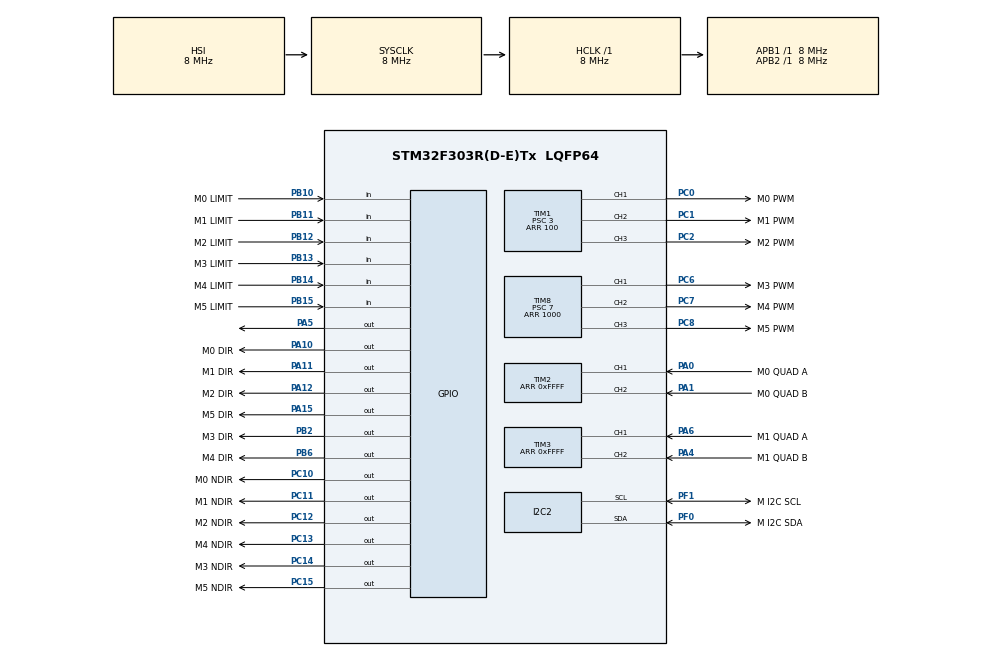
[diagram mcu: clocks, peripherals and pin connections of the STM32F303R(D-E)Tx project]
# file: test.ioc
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Mcu.Family=STM32F3
Mcu.Name=STM32F303R(D-E)Tx
Mcu.Package=LQFP64
Mcu.UserConstants=CONTROL_LOOP_PERIOD,1000;I2C_ADDRESS,0x10;CHANNELS,6;QUADRATURE_FILTER,8;PWM_PERIOD,10000
NVIC.PriorityGroup=NVIC_PRIORITYGROUP_4
NVIC.TIM6_DAC_IRQn=true\:1\:0\:true\:false\:true\:true\:true\:true
PA0.GPIO_Label=M0 QUAD A
PA0.Signal=S_TIM2_CH1_ETR
PA1.GPIO_Label=M0 QUAD B
PA1.Signal=S_TIM2_CH2
PA10.GPIO_Label=M0 DIR
PA10.Signal=GPIO_Output
PA11.GPIO_Label=M1 DIR
PA11.Signal=GPIO_Output
PA12.GPIO_Label=M2 DIR
PA12.Signal=GPIO_Output
PA15.GPIO_Label=M5 DIR
PA15.Signal=GPIO_Output
PA4.GPIO_Label=M1 QUAD B
PA4.Signal=S_TIM3_CH2
PA5.Signal=GPIO_Output
PA6.GPIO_Label=M1 QUAD A
PA6.Signal=S_TIM3_CH1
PB10.GPIO_Label=M0 LIMIT
PB10.GPIO_PuPd=GPIO_PULLUP
PB10.Signal=GPIO_Input
PB11.GPIO_Label=M1 LIMIT
PB11.GPIO_PuPd=GPIO_PULLUP
PB11.Signal=GPIO_Input
PB12.GPIO_Label=M2 LIMIT
PB12.GPIO_PuPd=GPIO_PULLUP
PB12.Signal=GPIO_Input
PB13.GPIO_Label=M3 LIMIT
PB13.GPIO_PuPd=GPIO_PULLUP
PB13.Signal=GPIO_Input
PB14.GPIO_Label=M4 LIMIT
PB14.GPIO_PuPd=GPIO_PULLUP
PB14.Signal=GPIO_Input
PB15.GPIO_Label=M5 LIMIT
PB15.GPIO_PuPd=GPIO_PULLUP
PB15.Signal=GPIO_Input
PB2.GPIO_Label=M3 DIR
PB2.Signal=GPIO_Output
PB6.GPIO_Label=M4 DIR
PB6.Signal=GPIO_Output
PB8.GPIO_Label=J I2C SCL
PB8.GPIO_Pu=GPIO_PULLUP
PB8.Signal=I2C1_SCL
PB9.GPIO_Label=J I2C SDA
PB9.GPIO_Pu=GPIO_PULLUP
PB9.Signal=I2C1_SDA
PC0.GPIO_Label=M0 PWM
PC0.Signal=S_TIM1_CH1
PC1.GPIO_Label=M1 PWM
PC1.Signal=S_TIM1_CH2
PC10.GPIO_Label=M0 NDIR
PC10.Signal=GPIO_Output
PC11.GPIO_Label=M1 NDIR
PC11.Signal=GPIO_Output
PC12.GPIO_Label=M2 NDIR
PC12.Signal=GPIO_Output
PC13.GPIO_Label=M4 NDIR
PC13.Signal=GPIO_Output
PC14-OSC32_IN.GPIO_Label=M3 NDIR
PC14-OSC32_IN.Signal=GPIO_Output
PC15-OSC32_OUT.GPIO_Label=M5 NDIR
PC15-OSC32_OUT.Signal=GPIO_Output
PC2.GPIO_Label=M2 PWM
PC2.Signal=S_TIM1_CH3
PC6.GPIO_Label=M3 PWM
PC6.Signal=S_TIM8_CH1
PC7.GPIO_Label=M4 PWM
PC7.Signal=S_TIM8_CH2
PC8.GPIO_Label=M5 PWM
PC8.Signal=S_TIM8_CH3
PF0-OSC_IN.GPIO_Label=M I2C SDA
PF0-OSC_IN.GPIO_Pu=GPIO_PULLUP
PF0-OSC_IN.Mode=I2C
PF0-OSC_IN.Signal=I2C2_SDA
PF1-OSC_OUT.GPIO_Label=M I2C SCL
PF1-OSC_OUT.GPIO_Pu=GPIO_PULLUP
PF1-OSC_OUT.Mode=I2C
PF1-OSC_OUT.Signal=I2C2_SCL
ProjectManager.HeapSize=0x200
ProjectManager.StackSize=0x400
ProjectManager.TargetToolchain=STM32CubeIDE
RCC.AHBFreq_Value=8000000
RCC.APB1Freq_Value=8000000
RCC.APB2Freq_Value=8000000
RCC.CortexFreq_Value=8000000
RCC.HSE_VALUE=8000000
RCC.HSI_VALUE=8000000
RCC.LSE_VALUE=32768
RCC.SYSCLKFreq_VALUE=8000000
RCC.USBFreq_Value=16000000
SH.S_TIM1_CH1.0=TIM1_CH1,PWM Generation1 CH1
SH.S_TIM1_CH2.0=TIM1_CH2,PWM Generation2 CH2
SH.S_TIM1_CH3.0=TIM1_CH3,PWM Generation3 CH3
SH.S_TIM2_CH1_ETR.0=TIM2_CH1,Encoder_Interface
SH.S_TIM2_CH2.0=TIM2_CH2,Encoder_Interface
SH.S_TIM3_CH1.0=TIM3_CH1,Encoder_Interface
SH.S_TIM3_CH2.0=TIM3_CH2,Encoder_Interface
SH.S_TIM8_CH1.0=TIM8_CH1,PWM Generation1 CH1
SH.S_TIM8_CH2.0=TIM8_CH2,PWM Generation2 CH2
SH.S_TIM8_CH3.0=TIM8_CH3,PWM Generation3 CH3
TIM1.Channel-PWM\ Generation1\ CH1=TIM_CHANNEL_1
TIM1.Channel-PWM\ Generation2\ CH2=TIM_CHANNEL_2
TIM1.Channel-PWM\ Generation3\ CH3=TIM_CHANNEL_3
TIM1.Period=100
TIM1.Prescaler=3
TIM2.IC1Filter=QUADRATURE_FILTER
TIM2.IC2Filter=QUADRATURE_FILTER
TIM2.Period=0xFFFF
TIM3.IC1Filter=QUADRATURE_FILTER
TIM3.IC2Filter=QUADRATURE_FILTER
TIM3.Period=0xFFFF
TIM6.Period=CONTROL_LOOP_PERIOD
TIM6.Prescaler=7
TIM8.Channel-PWM\ Generation1\ CH1=TIM_CHANNEL_1
TIM8.Channel-PWM\ Generation2\ CH2=TIM_CHANNEL_2
TIM8.Channel-PWM\ Generation3\ CH3=TIM_CHANNEL_3
TIM8.Period=1000
TIM8.Prescaler=7
VP_TIM1_VS_ClockSourceINT.Mode=Internal
VP_TIM6_VS_ClockSourceINT.Mode=Enable_Timer
VP_TIM8_VS_ClockSourceINT.Mode=Internal
board=custom

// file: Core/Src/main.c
/* USER CODE BEGIN Header */
/**
  ******************************************************************************
  * @file           : main.c
  * @brief          : Main program body
  ******************************************************************************
  * @attention
  *
  * <h2><center>&copy; Copyright (c) 2022 STMicroelectronics.
  * All rights reserved.</center></h2>
  *
  * This software component is licensed by ST under BSD 3-Clause license,
  * the "License"; You may not use this file except in compliance with the
  * License. You may obtain a copy of the License at:
  *                        opensource.org/licenses/BSD-3-Clause
  *
  ******************************************************************************
  */
/* USER CODE END Header */
#include "main.h"

I2C_HandleTypeDef hi2c2;

TIM_HandleTypeDef htim1;
TIM_HandleTypeDef htim2;
TIM_HandleTypeDef htim3;
TIM_HandleTypeDef htim6;
TIM_HandleTypeDef htim8;

void SystemClock_Config(void);
static void MX_GPIO_Init(void);
static void MX_I2C2_Init(void);
static void MX_TIM1_Init(void);
static void MX_TIM2_Init(void);
static void MX_TIM3_Init(void);
static void MX_TIM8_Init(void);
static void MX_TIM6_Init(void);

int main(void)
{

  /* MCU Configuration--------------------------------------------------------*/

  /* Reset of all peripherals, Initializes the Flash interface and the Systick. */
  HAL_Init();

  /* Configure the system clock */
  SystemClock_Config();

  /* Initialize all configured peripherals */
  MX_GPIO_Init();
  MX_I2C2_Init();
  MX_TIM1_Init();
  MX_TIM2_Init();
  MX_TIM3_Init();
  MX_TIM8_Init();
  MX_TIM6_Init();

  /* Infinite loop */
  /* USER CODE BEGIN WHILE */
  while (1)
  {
	  uint8_t buffer = 0xCC;
	  HAL_I2C_Master_Transmit(&hi2c2, 0x80, &buffer, sizeof(buffer), 100);
    /* USER CODE END WHILE */

  }
}

void SystemClock_Config(void)
{
  RCC_OscInitTypeDef RCC_OscInitStruct = {0};
  RCC_ClkInitTypeDef RCC_ClkInitStruct = {0};
  RCC_PeriphCLKInitTypeDef PeriphClkInit = {0};

  /** Initializes the RCC Oscillators according to the specified parameters
  * in the RCC_OscInitTypeDef structure.
  */
  RCC_OscInitStruct.OscillatorType = RCC_OSCILLATORTYPE_HSI;
  RCC_OscInitStruct.HSIState = RCC_HSI_ON;
  RCC_OscInitStruct.HSICalibrationValue = RCC_HSICALIBRATION_DEFAULT;
  RCC_OscInitStruct.PLL.PLLState = RCC_PLL_NONE;
  if (HAL_RCC_OscConfig(&RCC_OscInitStruct) != HAL_OK)
  {
    Error_Handler();
  }
  /** Initializes the CPU, AHB and APB buses clocks
  */
  RCC_ClkInitStruct.ClockType = RCC_CLOCKTYPE_HCLK|RCC_CLOCKTYPE_SYSCLK
                              |RCC_CLOCKTYPE_PCLK1|RCC_CLOCKTYPE_PCLK2;
  RCC_ClkInitStruct.SYSCLKSource = RCC_SYSCLKSOURCE_HSI;
  RCC_ClkInitStruct.AHBCLKDivider = RCC_SYSCLK_DIV1;
  RCC_ClkInitStruct.APB1CLKDivider = RCC_HCLK_DIV1;
  RCC_ClkInitStruct.APB2CLKDivider = RCC_HCLK_DIV1;

  if (HAL_RCC_ClockConfig(&RCC_ClkInitStruct, FLASH_LATENCY_0) != HAL_OK)
  {
    Error_Handler();
  }
  PeriphClkInit.PeriphClockSelection = RCC_PERIPHCLK_I2C2|RCC_PERIPHCLK_TIM1
                              |RCC_PERIPHCLK_TIM8|RCC_PERIPHCLK_TIM2
                              |RCC_PERIPHCLK_TIM34;
  PeriphClkInit.I2c2ClockSelection = RCC_I2C2CLKSOURCE_HSI;
  PeriphClkInit.Tim1ClockSelection = RCC_TIM1CLK_HCLK;
  PeriphClkInit.Tim8ClockSelection = RCC_TIM8CLK_HCLK;
  PeriphClkInit.Tim2ClockSelection = RCC_TIM2CLK_HCLK;
  PeriphClkInit.Tim34ClockSelection = RCC_TIM34CLK_HCLK;
  if (HAL_RCCEx_PeriphCLKConfig(&PeriphClkInit) != HAL_OK)
  {
    Error_Handler();
  }
}

static void MX_I2C2_Init(void)
{

  hi2c2.Instance = I2C2;
  hi2c2.Init.Timing = 0x2000090E;
  hi2c2.Init.OwnAddress1 = 0;
  hi2c2.Init.AddressingMode = I2C_ADDRESSINGMODE_7BIT;
  hi2c2.Init.DualAddressMode = I2C_DUALADDRESS_DISABLE;
  hi2c2.Init.OwnAddress2 = 0;
  hi2c2.Init.OwnAddress2Masks = I2C_OA2_NOMASK;
  hi2c2.Init.GeneralCallMode = I2C_GENERALCALL_DISABLE;
  hi2c2.Init.NoStretchMode = I2C_NOSTRETCH_DISABLE;
  if (HAL_I2C_Init(&hi2c2) != HAL_OK)
  {
    Error_Handler();
  }
  /** Configure Analogue filter
  */
  if (HAL_I2CEx_ConfigAnalogFilter(&hi2c2, I2C_ANALOGFILTER_ENABLE) != HAL_OK)
  {
    Error_Handler();
  }
  /** Configure Digital filter
  */
  if (HAL_I2CEx_ConfigDigitalFilter(&hi2c2, 0) != HAL_OK)
  {
    Error_Handler();
  }

}

static void MX_TIM1_Init(void)
{

  TIM_ClockConfigTypeDef sClockSourceConfig = {0};
  TIM_MasterConfigTypeDef sMasterConfig = {0};
  TIM_OC_InitTypeDef sConfigOC = {0};
  TIM_BreakDeadTimeConfigTypeDef sBreakDeadTimeConfig = {0};

  htim1.Instance = TIM1;
  htim1.Init.Prescaler = 3;
  htim1.Init.CounterMode = TIM_COUNTERMODE_UP;
  htim1.Init.Period = 100;
  htim1.Init.ClockDivision = TIM_CLOCKDIVISION_DIV1;
  htim1.Init.RepetitionCounter = 0;
  htim1.Init.AutoReloadPreload = TIM_AUTORELOAD_PRELOAD_DISABLE;
  if (HAL_TIM_Base_Init(&htim1) != HAL_OK)
  {
    Error_Handler();
  }
  sClockSourceConfig.ClockSource = TIM_CLOCKSOURCE_INTERNAL;
  if (HAL_TIM_ConfigClockSource(&htim1, &sClockSourceConfig) != HAL_OK)
  {
    Error_Handler();
  }
  if (HAL_TIM_PWM_Init(&htim1) != HAL_OK)
  {
    Error_Handler();
  }
  sMasterConfig.MasterOutputTrigger = TIM_TRGO_RESET;
  sMasterConfig.MasterOutputTrigger2 = TIM_TRGO2_RESET;
  sMasterConfig.MasterSlaveMode = TIM_MASTERSLAVEMODE_DISABLE;
  if (HAL_TIMEx_MasterConfigSynchronization(&htim1, &sMasterConfig) != HAL_OK)
  {
    Error_Handler();
  }
  sConfigOC.OCMode = TIM_OCMODE_PWM1;
  sConfigOC.Pulse = 0;
  sConfigOC.OCPolarity = TIM_OCPOLARITY_HIGH;
  sConfigOC.OCNPolarity = TIM_OCNPOLARITY_HIGH;
  sConfigOC.OCFastMode = TIM_OCFAST_DISABLE;
  sConfigOC.OCIdleState = TIM_OCIDLESTATE_RESET;
  sConfigOC.OCNIdleState = TIM_OCNIDLESTATE_RESET;
  if (HAL_TIM_PWM_ConfigChannel(&htim1, &sConfigOC, TIM_CHANNEL_1) != HAL_OK)
  {
    Error_Handler();
  }
  if (HAL_TIM_PWM_ConfigChannel(&htim1, &sConfigOC, TIM_CHANNEL_2) != HAL_OK)
  {
    Error_Handler();
  }
  if (HAL_TIM_PWM_ConfigChannel(&htim1, &sConfigOC, TIM_CHANNEL_3) != HAL_OK)
  {
    Error_Handler();
  }
  sBreakDeadTimeConfig.OffStateRunMode = TIM_OSSR_DISABLE;
  sBreakDeadTimeConfig.OffStateIDLEMode = TIM_OSSI_DISABLE;
  sBreakDeadTimeConfig.LockLevel = TIM_LOCKLEVEL_OFF;
  sBreakDeadTimeConfig.DeadTime = 0;
  sBreakDeadTimeConfig.BreakState = TIM_BREAK_DISABLE;
  sBreakDeadTimeConfig.BreakPolarity = TIM_BREAKPOLARITY_HIGH;
  sBreakDeadTimeConfig.BreakFilter = 0;
  sBreakDeadTimeConfig.Break2State = TIM_BREAK2_DISABLE;
  sBreakDeadTimeConfig.Break2Polarity = TIM_BREAK2POLARITY_HIGH;
  sBreakDeadTimeConfig.Break2Filter = 0;
  sBreakDeadTimeConfig.AutomaticOutput = TIM_AUTOMATICOUTPUT_DISABLE;
  if (HAL_TIMEx_ConfigBreakDeadTime(&htim1, &sBreakDeadTimeConfig) != HAL_OK)
  {
    Error_Handler();
  }
  HAL_TIM_MspPostInit(&htim1);

}

static void MX_TIM2_Init(void)
{

  TIM_Encoder_InitTypeDef sConfig = {0};
  TIM_MasterConfigTypeDef sMasterConfig = {0};

  htim2.Instance = TIM2;
  htim2.Init.Prescaler = 0;
  htim2.Init.CounterMode = TIM_COUNTERMODE_UP;
  htim2.Init.Period = 0xFFFF;
  htim2.Init.ClockDivision = TIM_CLOCKDIVISION_DIV1;
  htim2.Init.AutoReloadPreload = TIM_AUTORELOAD_PRELOAD_DISABLE;
  sConfig.EncoderMode = TIM_ENCODERMODE_TI1;
  sConfig.IC1Polarity = TIM_ICPOLARITY_RISING;
  sConfig.IC1Selection = TIM_ICSELECTION_DIRECTTI;
  sConfig.IC1Prescaler = TIM_ICPSC_DIV1;
  sConfig.IC1Filter = QUADRATURE_FILTER;
  sConfig.IC2Polarity = TIM_ICPOLARITY_RISING;
  sConfig.IC2Selection = TIM_ICSELECTION_DIRECTTI;
  sConfig.IC2Prescaler = TIM_ICPSC_DIV1;
  sConfig.IC2Filter = QUADRATURE_FILTER;
  if (HAL_TIM_Encoder_Init(&htim2, &sConfig) != HAL_OK)
  {
    Error_Handler();
  }
  sMasterConfig.MasterOutputTrigger = TIM_TRGO_RESET;
  sMasterConfig.MasterSlaveMode = TIM_MASTERSLAVEMODE_DISABLE;
  if (HAL_TIMEx_MasterConfigSynchronization(&htim2, &sMasterConfig) != HAL_OK)
  {
    Error_Handler();
  }

}

static void MX_TIM3_Init(void)
{

  TIM_Encoder_InitTypeDef sConfig = {0};
  TIM_MasterConfigTypeDef sMasterConfig = {0};

  htim3.Instance = TIM3;
  htim3.Init.Prescaler = 0;
  htim3.Init.CounterMode = TIM_COUNTERMODE_UP;
  htim3.Init.Period = 0xFFFF;
  htim3.Init.ClockDivision = TIM_CLOCKDIVISION_DIV1;
  htim3.Init.AutoReloadPreload = TIM_AUTORELOAD_PRELOAD_DISABLE;
  sConfig.EncoderMode = TIM_ENCODERMODE_TI1;
  sConfig.IC1Polarity = TIM_ICPOLARITY_RISING;
  sConfig.IC1Selection = TIM_ICSELECTION_DIRECTTI;
  sConfig.IC1Prescaler = TIM_ICPSC_DIV1;
  sConfig.IC1Filter = QUADRATURE_FILTER;
  sConfig.IC2Polarity = TIM_ICPOLARITY_RISING;
  sConfig.IC2Selection = TIM_ICSELECTION_DIRECTTI;
  sConfig.IC2Prescaler = TIM_ICPSC_DIV1;
  sConfig.IC2Filter = QUADRATURE_FILTER;
  if (HAL_TIM_Encoder_Init(&htim3, &sConfig) != HAL_OK)
  {
    Error_Handler();
  }
  sMasterConfig.MasterOutputTrigger = TIM_TRGO_RESET;
  sMasterConfig.MasterSlaveMode = TIM_MASTERSLAVEMODE_DISABLE;
  if (HAL_TIMEx_MasterConfigSynchronization(&htim3, &sMasterConfig) != HAL_OK)
  {
    Error_Handler();
  }

}

static void MX_TIM6_Init(void)
{

  TIM_MasterConfigTypeDef sMasterConfig = {0};

  htim6.Instance = TIM6;
  htim6.Init.Prescaler = 7;
  htim6.Init.CounterMode = TIM_COUNTERMODE_UP;
  htim6.Init.Period = CONTROL_LOOP_PERIOD;
  htim6.Init.AutoReloadPreload = TIM_AUTORELOAD_PRELOAD_DISABLE;
  if (HAL_TIM_Base_Init(&htim6) != HAL_OK)
  {
    Error_Handler();
  }
  sMasterConfig.MasterOutputTrigger = TIM_TRGO_RESET;
  sMasterConfig.MasterSlaveMode = TIM_MASTERSLAVEMODE_DISABLE;
  if (HAL_TIMEx_MasterConfigSynchronization(&htim6, &sMasterConfig) != HAL_OK)
  {
    Error_Handler();
  }

}

static void MX_TIM8_Init(void)
{

  TIM_ClockConfigTypeDef sClockSourceConfig = {0};
  TIM_MasterConfigTypeDef sMasterConfig = {0};
  TIM_OC_InitTypeDef sConfigOC = {0};
  TIM_BreakDeadTimeConfigTypeDef sBreakDeadTimeConfig = {0};

  htim8.Instance = TIM8;
  htim8.Init.Prescaler = 7;
  htim8.Init.CounterMode = TIM_COUNTERMODE_UP;
  htim8.Init.Period = 1000;
  htim8.Init.ClockDivision = TIM_CLOCKDIVISION_DIV1;
  htim8.Init.RepetitionCounter = 0;
  htim8.Init.AutoReloadPreload = TIM_AUTORELOAD_PRELOAD_DISABLE;
  if (HAL_TIM_Base_Init(&htim8) != HAL_OK)
  {
    Error_Handler();
  }
  sClockSourceConfig.ClockSource = TIM_CLOCKSOURCE_INTERNAL;
  if (HAL_TIM_ConfigClockSource(&htim8, &sClockSourceConfig) != HAL_OK)
  {
    Error_Handler();
  }
  if (HAL_TIM_PWM_Init(&htim8) != HAL_OK)
  {
    Error_Handler();
  }
  sMasterConfig.MasterOutputTrigger = TIM_TRGO_RESET;
  sMasterConfig.MasterOutputTrigger2 = TIM_TRGO2_RESET;
  sMasterConfig.MasterSlaveMode = TIM_MASTERSLAVEMODE_DISABLE;
  if (HAL_TIMEx_MasterConfigSynchronization(&htim8, &sMasterConfig) != HAL_OK)
  {
    Error_Handler();
  }
  sConfigOC.OCMode = TIM_OCMODE_PWM1;
  sConfigOC.Pulse = 0;
  sConfigOC.OCPolarity = TIM_OCPOLARITY_HIGH;
  sConfigOC.OCNPolarity = TIM_OCNPOLARITY_HIGH;
  sConfigOC.OCFastMode = TIM_OCFAST_DISABLE;
  sConfigOC.OCIdleState = TIM_OCIDLESTATE_RESET;
  sConfigOC.OCNIdleState = TIM_OCNIDLESTATE_RESET;
  if (HAL_TIM_PWM_ConfigChannel(&htim8, &sConfigOC, TIM_CHANNEL_1) != HAL_OK)
  {
    Error_Handler();
  }
  if (HAL_TIM_PWM_ConfigChannel(&htim8, &sConfigOC, TIM_CHANNEL_2) != HAL_OK)
  {
    Error_Handler();
  }
  if (HAL_TIM_PWM_ConfigChannel(&htim8, &sConfigOC, TIM_CHANNEL_3) != HAL_OK)
  {
    Error_Handler();
  }
  sBreakDeadTimeConfig.OffStateRunMode = TIM_OSSR_DISABLE;
  sBreakDeadTimeConfig.OffStateIDLEMode = TIM_OSSI_DISABLE;
  sBreakDeadTimeConfig.LockLevel = TIM_LOCKLEVEL_OFF;
  sBreakDeadTimeConfig.DeadTime = 0;
  sBreakDeadTimeConfig.BreakState = TIM_BREAK_DISABLE;
  sBreakDeadTimeConfig.BreakPolarity = TIM_BREAKPOLARITY_HIGH;
  sBreakDeadTimeConfig.BreakFilter = 0;
  sBreakDeadTimeConfig.Break2State = TIM_BREAK2_DISABLE;
  sBreakDeadTimeConfig.Break2Polarity = TIM_BREAK2POLARITY_HIGH;
  sBreakDeadTimeConfig.Break2Filter = 0;
  sBreakDeadTimeConfig.AutomaticOutput = TIM_AUTOMATICOUTPUT_DISABLE;
  if (HAL_TIMEx_ConfigBreakDeadTime(&htim8, &sBreakDeadTimeConfig) != HAL_OK)
  {
    Error_Handler();
  }
  HAL_TIM_MspPostInit(&htim8);

}

static void MX_GPIO_Init(void)
{
  GPIO_InitTypeDef GPIO_InitStruct = {0};

  /* GPIO Ports Clock Enable */
  __HAL_RCC_GPIOC_CLK_ENABLE();
  __HAL_RCC_GPIOF_CLK_ENABLE();
  __HAL_RCC_GPIOA_CLK_ENABLE();
  __HAL_RCC_GPIOB_CLK_ENABLE();

  /*Configure GPIO pin Output Level */
  HAL_GPIO_WritePin(GPIOC, M4_NDIR_Pin|M3_NDIR_Pin|M5_NDIR_Pin|M0_NDIR_Pin
                          |M1_NDIR_Pin|M2_NDIR_Pin, GPIO_PIN_RESET);

  /*Configure GPIO pin Output Level */
  HAL_GPIO_WritePin(GPIOA, GPIO_PIN_5|M0_DIR_Pin|M1_DIR_Pin|M2_DIR_Pin
                          |M5_DIR_Pin, GPIO_PIN_RESET);

  /*Configure GPIO pin Output Level */
  HAL_GPIO_WritePin(GPIOB, M3_DIR_Pin|M4_DIR_Pin, GPIO_PIN_RESET);

  /*Configure GPIO pins : M4_NDIR_Pin M3_NDIR_Pin M5_NDIR_Pin M0_NDIR_Pin
                           M1_NDIR_Pin M2_NDIR_Pin */
  GPIO_InitStruct.Pin = M4_NDIR_Pin|M3_NDIR_Pin|M5_NDIR_Pin|M0_NDIR_Pin
                          |M1_NDIR_Pin|M2_NDIR_Pin;
  GPIO_InitStruct.Mode = GPIO_MODE_OUTPUT_PP;
  GPIO_InitStruct.Pull = GPIO_NOPULL;
  GPIO_InitStruct.Speed = GPIO_SPEED_FREQ_LOW;
  HAL_GPIO_Init(GPIOC, &GPIO_InitStruct);

  /*Configure GPIO pins : PA5 M0_DIR_Pin M1_DIR_Pin M2_DIR_Pin
                           M5_DIR_Pin */
  GPIO_InitStruct.Pin = GPIO_PIN_5|M0_DIR_Pin|M1_DIR_Pin|M2_DIR_Pin
                          |M5_DIR_Pin;
  GPIO_InitStruct.Mode = GPIO_MODE_OUTPUT_PP;
  GPIO_InitStruct.Pull = GPIO_NOPULL;
  GPIO_InitStruct.Speed = GPIO_SPEED_FREQ_LOW;
  HAL_GPIO_Init(GPIOA, &GPIO_InitStruct);

  /*Configure GPIO pins : M3_DIR_Pin M4_DIR_Pin */
  GPIO_InitStruct.Pin = M3_DIR_Pin|M4_DIR_Pin;
  GPIO_InitStruct.Mode = GPIO_MODE_OUTPUT_PP;
  GPIO_InitStruct.Pull = GPIO_NOPULL;
  GPIO_InitStruct.Speed = GPIO_SPEED_FREQ_LOW;
  HAL_GPIO_Init(GPIOB, &GPIO_InitStruct);

  /*Configure GPIO pins : M0_LIMIT_Pin M1_LIMIT_Pin M2_LIMIT_Pin M3_LIMIT_Pin
                           M4_LIMIT_Pin M5_LIMIT_Pin */
  GPIO_InitStruct.Pin = M0_LIMIT_Pin|M1_LIMIT_Pin|M2_LIMIT_Pin|M3_LIMIT_Pin
                          |M4_LIMIT_Pin|M5_LIMIT_Pin;
  GPIO_InitStruct.Mode = GPIO_MODE_INPUT;
  GPIO_InitStruct.Pull = GPIO_PULLUP;
  HAL_GPIO_Init(GPIOB, &GPIO_InitStruct);

  /*Configure GPIO pins : J_I2C_SCL_Pin J_I2C_SDA_Pin */
  GPIO_InitStruct.Pin = J_I2C_SCL_Pin|J_I2C_SDA_Pin;
  GPIO_InitStruct.Mode = GPIO_MODE_AF_OD;
  GPIO_InitStruct.Pull = GPIO_PULLUP;
  GPIO_InitStruct.Speed = GPIO_SPEED_FREQ_HIGH;
  GPIO_InitStruct.Alternate = GPIO_AF4_I2C1;
  HAL_GPIO_Init(GPIOB, &GPIO_InitStruct);

}

void Error_Handler(void)
{
  __disable_irq();
  while (1)
  {
  }
}

/************************ (C) COPYRIGHT STMicroelectronics *****END OF FILE****/
